VERSION ""

NS_ :

BS_:

BU_:

BO_ 3221225472 VECTOR__INDEPENDENT_SIG_MSG: 0 Vector__XXX
 SG_ NewSignal_0010 : 32|8@1+ (1,0) [0|0] "" Vector__XXX
 SG_ NewSignal_0021 : 16|8@1+ (1,0) [0|0] "" Vector__XXX
 SG_ Throttle_1 : 16|8@1+ (1,0) [0|0] "" Vector__XXX
 SG_ Throttle_1 : 16|8@1+ (1,0) [0|0] "" Vector__XXX
 SG_ Battery_Voltage : 0|16@1+ (0.001,0) [0|0] "V" Vector__XXX

BO_ 1537 BC: 8 Vector__XXX
 SG_ Battery_Current : 0|32@1- (-0.001,0) [0|0] "A" Vector__XXX

BO_ 396 VS: 8 Vector__XXX
 SG_ Vehicle_Speed : 8|12@1- (0.1,0) [0|0] "Kmph" Vector__XXX

BO_ 652 VT: 8 Vector__XXX
 SG_ Throttle_2 : 24|16@1+ (0.006,0) [0|0] "" Vector__XXX

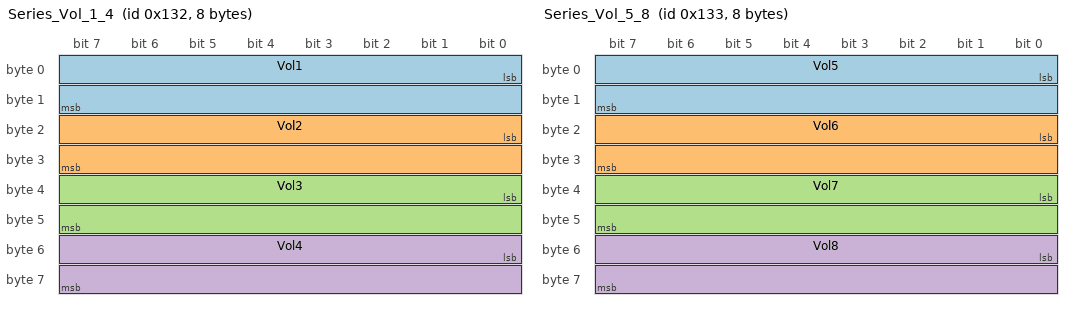
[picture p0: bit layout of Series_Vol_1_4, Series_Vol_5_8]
BO_ 306 Series_Vol_1_4: 8 Vector__XXX
 SG_ Vol1 : 0|16@1+ (0.0001,0) [0|0] "V" Vector__XXX
 SG_ Vol2 : 16|16@1+ (0.0001,0) [0|0] "V" Vector__XXX
 SG_ Vol3 : 32|16@1+ (0.0001,0) [0|0] "V" Vector__XXX
 SG_ Vol4 : 48|16@1+ (0.0001,0) [0|0] "V" Vector__XXX

BO_ 307 Series_Vol_5_8: 8 Vector__XXX
 SG_ Vol5 : 0|16@1+ (0.0001,0) [0|0] "V" Vector__XXX
 SG_ Vol6 : 16|16@1+ (0.0001,0) [0|0] "V" Vector__XXX
 SG_ Vol7 : 32|16@1+ (0.0001,0) [0|0] "V" Vector__XXX
 SG_ Vol8 : 48|16@1+ (0.0001,0) [0|0] "V" Vector__XXX

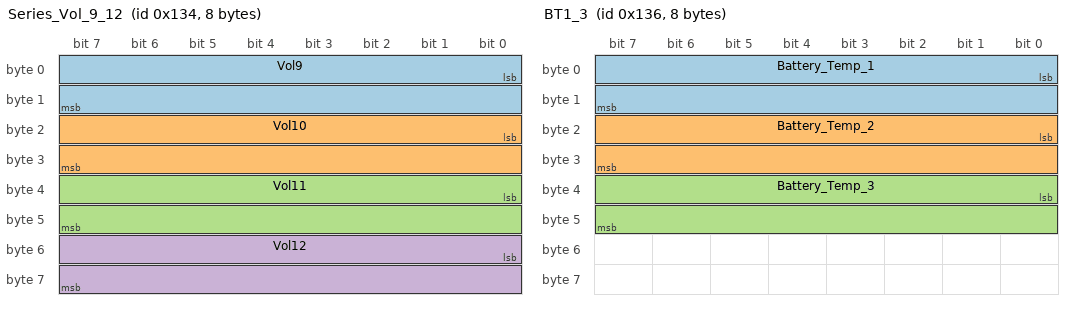
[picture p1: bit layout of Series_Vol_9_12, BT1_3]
BO_ 308 Series_Vol_9_12: 8 Vector__XXX
 SG_ Vol9 : 0|16@1+ (0.0001,0) [0|0] "V" Vector__XXX
 SG_ Vol10 : 16|16@1+ (0.0001,0) [0|0] "V" Vector__XXX
 SG_ Vol11 : 32|16@1+ (0.0001,0) [0|0] "V" Vector__XXX
 SG_ Vol12 : 48|16@1+ (0.0001,0) [0|0] "V" Vector__XXX

BO_ 309 Series_Vol_13_14: 8 Vector__XXX
 SG_ Vol13 : 0|16@1+ (0.0001,0) [0|0] "V" Vector__XXX
 SG_ Vol14 : 16|16@1+ (0.0001,0) [0|0] "V" Vector__XXX

BO_ 310 BT1_3: 8 Vector__XXX
 SG_ Battery_Temp_1 : 0|16@1+ (0.01,0) [0|0] " deg C" Vector__XXX
 SG_ Battery_Temp_2 : 16|16@1+ (0.01,0) [0|0] " deg C" Vector__XXX
 SG_ Battery_Temp_3 : 32|16@1+ (0.01,0) [0|0] " deg C" Vector__XXX

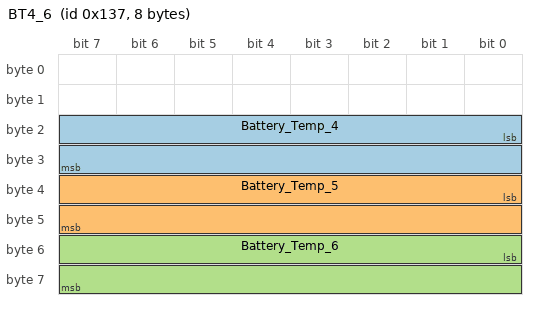
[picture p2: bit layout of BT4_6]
BO_ 311 BT4_6: 8 Vector__XXX
 SG_ Battery_Temp_4 : 16|16@1+ (0.01,0) [0|0] " deg C" Vector__XXX
 SG_ Battery_Temp_5 : 32|16@1+ (0.01,0) [0|0] " deg C" Vector__XXX
 SG_ Battery_Temp_6 : 48|16@1+ (0.01,0) [0|0] " deg C" Vector__XXX

BO_ 517 KS: 8 Vector__XXX
 SG_ Key_Switch : 4|1@1+ (1,0) [0|0] "" Vector__XXX

BO_ 257 DM: 8 Vector__XXX
 SG_ Drive_Mode : 0|1@1+ (1,0) [0|0] "" Vector__XXX

BO_ 521 SOC: 8 Vector__XXX
 SG_ Battery_SOC : 32|8@1+ (1,0) [0|0] "%" Vector__XXX

BO_ 2 CS: 8 Vector__XXX
 SG_ Charger_Status : 0|8@1+ (1,0) [0|0] "" Vector__XXX

BO_ 3 CC: 8 Vector__XXX
 SG_ Charger_Current : 32|16@1+ (0.001,0) [0|0] "A" Vector__XXX
